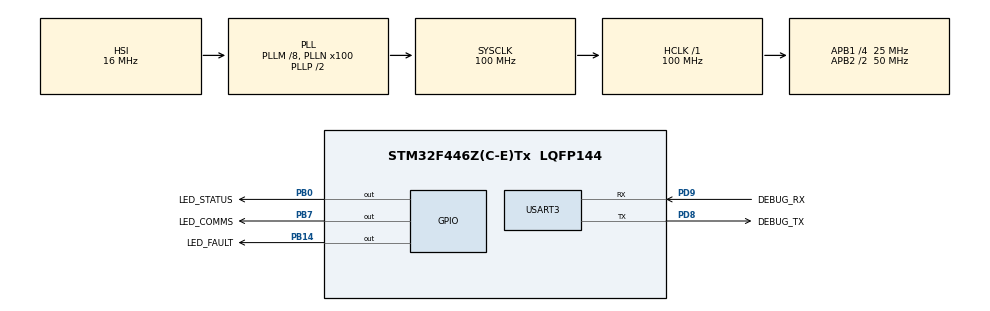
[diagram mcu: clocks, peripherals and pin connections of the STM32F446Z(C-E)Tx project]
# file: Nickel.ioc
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Dma.Request0=USART3_TX
Dma.USART3_TX.0.Direction=DMA_MEMORY_TO_PERIPH
Dma.USART3_TX.0.FIFOMode=DMA_FIFOMODE_DISABLE
Dma.USART3_TX.0.Instance=DMA1_Stream3
Dma.USART3_TX.0.MemDataAlignment=DMA_MDATAALIGN_BYTE
Dma.USART3_TX.0.MemInc=DMA_MINC_ENABLE
Dma.USART3_TX.0.Mode=DMA_NORMAL
Dma.USART3_TX.0.PeriphDataAlignment=DMA_PDATAALIGN_BYTE
Dma.USART3_TX.0.PeriphInc=DMA_PINC_DISABLE
Dma.USART3_TX.0.Priority=DMA_PRIORITY_LOW
Mcu.Family=STM32F4
Mcu.Name=STM32F446Z(C-E)Tx
Mcu.Package=LQFP144
NVIC.DMA1_Stream3_IRQn=true\:0\:0\:false\:false\:true\:false\:true\:true
NVIC.PriorityGroup=NVIC_PRIORITYGROUP_4
NVIC.USART3_IRQn=true\:7\:0\:true\:false\:true\:false\:true\:true
PA13.Mode=Trace_Asynchronous_SW
PA13.Signal=SYS_JTMS-SWDIO
PA14.Mode=Trace_Asynchronous_SW
PA14.Signal=SYS_JTCK-SWCLK
PB0.GPIO_Label=LED_STATUS
PB0.Signal=GPIO_Output
PB14.GPIO_Label=LED_FAULT
PB14.Signal=GPIO_Output
PB3.Mode=Trace_Asynchronous_SW
PB3.Signal=SYS_JTDO-SWO
PB7.GPIO_Label=LED_COMMS
PB7.Signal=GPIO_Output
PD8.GPIO_Label=DEBUG_TX
PD8.Mode=Asynchronous
PD8.Signal=USART3_TX
PD9.GPIO_Label=DEBUG_RX
PD9.Mode=Asynchronous
PD9.Signal=USART3_RX
ProjectManager.HeapSize=0x200
ProjectManager.StackSize=0x400
ProjectManager.TargetToolchain=CMake
RCC.AHBFreq_Value=100000000
RCC.APB1CLKDivider=RCC_HCLK_DIV4
RCC.APB1Freq_Value=25000000
RCC.APB1TimFreq_Value=50000000
RCC.APB2CLKDivider=RCC_HCLK_DIV2
RCC.APB2Freq_Value=50000000
RCC.APB2TimFreq_Value=100000000
RCC.CortexFreq_Value=100000000
RCC.HCLKFreq_Value=100000000
RCC.PLLM=8
RCC.PLLN=100
RCC.SYSCLKFreq_VALUE=100000000
RCC.SYSCLKSource=RCC_SYSCLKSOURCE_PLLCLK
RCC.USBFreq_Value=100000000
RCC.VCOOutputFreq_Value=200000000
TIM2.AutoReloadPreload=TIM_AUTORELOAD_PRELOAD_ENABLE
USART3.VirtualMode=VM_ASYNC
VP_TIM2_VS_ClockSourceINT.Mode=Internal
board=custom

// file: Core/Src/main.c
/* USER CODE BEGIN Header */
/**
  ******************************************************************************
  * @file           : main.c
  * @brief          : Main program body
  ******************************************************************************
  * @attention
  *
  * Copyright (c) 2026 STMicroelectronics.
  * All rights reserved.
  *
  * This software is licensed under terms that can be found in the LICENSE file
  * in the root directory of this software component.
  * If no LICENSE file comes with this software, it is provided AS-IS.
  *
  ******************************************************************************
  */
/* USER CODE END Header */
#include "main.h"

/* USER CODE BEGIN Includes */
#include "app.hpp"
/* USER CODE END Includes */

TIM_HandleTypeDef htim2;

UART_HandleTypeDef huart3;
DMA_HandleTypeDef hdma_usart3_tx;

void SystemClock_Config(void);
static void MX_GPIO_Init(void);
static void MX_DMA_Init(void);
static void MX_USART3_UART_Init(void);
static void MX_TIM2_Init(void);

int main(void)
{

  /* MCU Configuration--------------------------------------------------------*/

  /* Reset of all peripherals, Initializes the Flash interface and the Systick. */
  HAL_Init();

  /* Configure the system clock */
  SystemClock_Config();

  /* Initialize all configured peripherals */
  MX_GPIO_Init();
  MX_DMA_Init();
  MX_USART3_UART_Init();
  MX_TIM2_Init();
  /* USER CODE BEGIN 2 */

  app_init();
  app_run();

  /* USER CODE END 2 */

  /* Infinite loop */
  while (1)
  {

  }
}

void SystemClock_Config(void)
{
  RCC_OscInitTypeDef RCC_OscInitStruct = {0};
  RCC_ClkInitTypeDef RCC_ClkInitStruct = {0};

  /** Configure the main internal regulator output voltage
  */
  __HAL_RCC_PWR_CLK_ENABLE();
  __HAL_PWR_VOLTAGESCALING_CONFIG(PWR_REGULATOR_VOLTAGE_SCALE3);

  /** Initializes the RCC Oscillators according to the specified parameters
  * in the RCC_OscInitTypeDef structure.
  */
  RCC_OscInitStruct.OscillatorType = RCC_OSCILLATORTYPE_HSI;
  RCC_OscInitStruct.HSIState = RCC_HSI_ON;
  RCC_OscInitStruct.HSICalibrationValue = RCC_HSICALIBRATION_DEFAULT;
  RCC_OscInitStruct.PLL.PLLState = RCC_PLL_ON;
  RCC_OscInitStruct.PLL.PLLSource = RCC_PLLSOURCE_HSI;
  RCC_OscInitStruct.PLL.PLLM = 8;
  RCC_OscInitStruct.PLL.PLLN = 100;
  RCC_OscInitStruct.PLL.PLLP = RCC_PLLP_DIV2;
  RCC_OscInitStruct.PLL.PLLQ = 2;
  RCC_OscInitStruct.PLL.PLLR = 2;
  if (HAL_RCC_OscConfig(&RCC_OscInitStruct) != HAL_OK)
  {
    Error_Handler();
  }

  /** Initializes the CPU, AHB and APB buses clocks
  */
  RCC_ClkInitStruct.ClockType = RCC_CLOCKTYPE_HCLK|RCC_CLOCKTYPE_SYSCLK
                              |RCC_CLOCKTYPE_PCLK1|RCC_CLOCKTYPE_PCLK2;
  RCC_ClkInitStruct.SYSCLKSource = RCC_SYSCLKSOURCE_PLLCLK;
  RCC_ClkInitStruct.AHBCLKDivider = RCC_SYSCLK_DIV1;
  RCC_ClkInitStruct.APB1CLKDivider = RCC_HCLK_DIV4;
  RCC_ClkInitStruct.APB2CLKDivider = RCC_HCLK_DIV2;

  if (HAL_RCC_ClockConfig(&RCC_ClkInitStruct, FLASH_LATENCY_3) != HAL_OK)
  {
    Error_Handler();
  }
}

static void MX_TIM2_Init(void)
{

  /* USER CODE BEGIN TIM2_Init 0 */
    /**
     *  TIM2 is used by Nickel for timer.hpp as a [us] hardware timer. Do not alter
     */
  /* USER CODE END TIM2_Init 0 */

  TIM_ClockConfigTypeDef sClockSourceConfig = {0};
  TIM_MasterConfigTypeDef sMasterConfig = {0};

  htim2.Instance = TIM2;
  htim2.Init.Prescaler = 0;
  htim2.Init.CounterMode = TIM_COUNTERMODE_UP;
  htim2.Init.Period = 4294967295;
  htim2.Init.ClockDivision = TIM_CLOCKDIVISION_DIV1;
  htim2.Init.AutoReloadPreload = TIM_AUTORELOAD_PRELOAD_ENABLE;
  if (HAL_TIM_Base_Init(&htim2) != HAL_OK)
  {
    Error_Handler();
  }
  sClockSourceConfig.ClockSource = TIM_CLOCKSOURCE_INTERNAL;
  if (HAL_TIM_ConfigClockSource(&htim2, &sClockSourceConfig) != HAL_OK)
  {
    Error_Handler();
  }
  sMasterConfig.MasterOutputTrigger = TIM_TRGO_RESET;
  sMasterConfig.MasterSlaveMode = TIM_MASTERSLAVEMODE_DISABLE;
  if (HAL_TIMEx_MasterConfigSynchronization(&htim2, &sMasterConfig) != HAL_OK)
  {
    Error_Handler();
  }

}

static void MX_USART3_UART_Init(void)
{

  huart3.Instance = USART3;
  huart3.Init.BaudRate = 115200;
  huart3.Init.WordLength = UART_WORDLENGTH_8B;
  huart3.Init.StopBits = UART_STOPBITS_1;
  huart3.Init.Parity = UART_PARITY_NONE;
  huart3.Init.Mode = UART_MODE_TX_RX;
  huart3.Init.HwFlowCtl = UART_HWCONTROL_NONE;
  huart3.Init.OverSampling = UART_OVERSAMPLING_16;
  if (HAL_UART_Init(&huart3) != HAL_OK)
  {
    Error_Handler();
  }

}

static void MX_DMA_Init(void)
{

  /* DMA controller clock enable */
  __HAL_RCC_DMA1_CLK_ENABLE();

  /* DMA interrupt init */
  /* DMA1_Stream3_IRQn interrupt configuration */
  HAL_NVIC_SetPriority(DMA1_Stream3_IRQn, 0, 0);
  HAL_NVIC_EnableIRQ(DMA1_Stream3_IRQn);

}

static void MX_GPIO_Init(void)
{
  GPIO_InitTypeDef GPIO_InitStruct = {0};

  /* GPIO Ports Clock Enable */
  __HAL_RCC_GPIOB_CLK_ENABLE();
  __HAL_RCC_GPIOD_CLK_ENABLE();
  __HAL_RCC_GPIOA_CLK_ENABLE();

  /*Configure GPIO pin Output Level */
  HAL_GPIO_WritePin(GPIOB, LED_STATUS_Pin|LED_FAULT_Pin|LED_COMMS_Pin, GPIO_PIN_RESET);

  /*Configure GPIO pins : LED_STATUS_Pin LED_FAULT_Pin LED_COMMS_Pin */
  GPIO_InitStruct.Pin = LED_STATUS_Pin|LED_FAULT_Pin|LED_COMMS_Pin;
  GPIO_InitStruct.Mode = GPIO_MODE_OUTPUT_PP;
  GPIO_InitStruct.Pull = GPIO_NOPULL;
  GPIO_InitStruct.Speed = GPIO_SPEED_FREQ_LOW;
  HAL_GPIO_Init(GPIOB, &GPIO_InitStruct);

}

void Error_Handler(void)
{
  __disable_irq();
  while (1)
  {
  }
}
